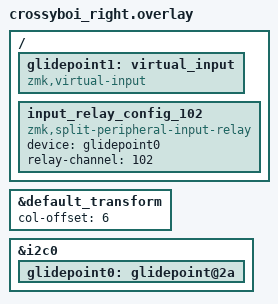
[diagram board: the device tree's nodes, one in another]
/*
 * Copyright (c) 2022 The ZMK Contributors
 *
 * SPDX-License-Identifier: MIT
 */

#include "crossyboi.dtsi"

&default_transform {
  col-offset = <6>;
};

/*
&right_encoder {
  status = "okay";
};

&chosen {
  zephyr,display = &nice_view;
};

&nice_view_spi {
  status = "okay";
};

&nice_view {
  status = "okay";
};
*/

&i2c0 {
    status = "okay";
    glidepoint0: glidepoint@2a {
        status = "okay";
    };
};

/ {
    /* THIS only makes keymap binding happy, nothing happens on peripheral side */
	glidepoint1: virtual_input {
		compatible = "zmk,virtual-input";
	};

    input_relay_config_102 {
        compatible = "zmk,split-peripheral-input-relay";

        /* peripheral side input device, used to... */
		/*  - be intecepted on peripheral; */
		/*  - and then, be resurrected as `zmk,virtual-device` on central; */
        device = <&glidepoint0>;

        /* channel id, used to be be transfered along with all input events. */
		/* NOTE 1: pick any 8bit integer. (1 - 255) */
		/* NOTE 2: should matching relay-channel on central overlay */
		relay-channel = <102>;
    };
};
